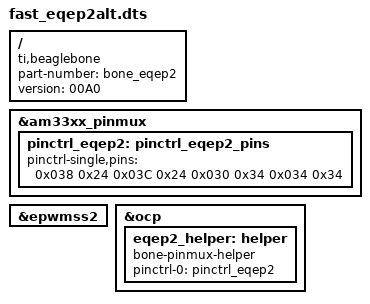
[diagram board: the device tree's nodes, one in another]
/*
 * Copyright (C) 2013 Nathaniel R. Lewis - http://teknoman117.wordpress.com/
 *
 * This program is free software; you can redistribute it and/or modify
 * it under the terms of the GNU General Public License version 2 as
 * published by the Free Software Foundation.
 * 
 * Enable eQEP2 on the Beaglebone White and Black
 */
/dts-v1/;
/plugin/;

/ {
    compatible = "ti,beaglebone", "ti,beaglebone-black";

    /* identification */
    part-number = "bone_eqep2";
    version     = "00A0";

    fragment@0 {
        target = <&am33xx_pinmux>;
        __overlay__ {
            pinctrl_eqep2: pinctrl_eqep2_pins {
                pinctrl-single,pins = <					 				   
		                0x038 0x24  /* P8_16 = GPIO2_12 = EQEP2_index, MODE4 */
		                0x03C 0x24  /* P8_15 = GPIO2_13 = EQEP2_strobe, MODE4 */
		                0x030 0x34  /* P8_12 = GPIO2_10 = EQEP2A_in, MODE4 */
		                0x034 0x34  /* P8_11 = GPIO2_11 = EQEP2B_in, MODE4 */
                >;
            };
        };
    };
    
    fragment@1 {
        target = <&epwmss2>;
        __overlay__ {
            status = "okay";
        };
    };
    
    fragment@2 {
            target = <&ocp>;
            __overlay__ {
                eqep2_helper: helper {
                    compatible = "bone-pinmux-helper";
                    pinctrl-names = "default";
                    pinctrl-0 = <&pinctrl_eqep2>;
                    status = "okay";
                };
            };
        };
    
};
